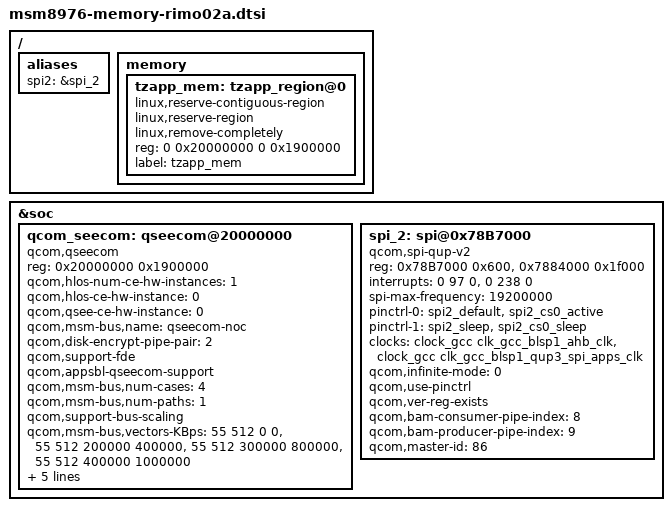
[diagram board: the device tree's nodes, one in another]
/ {
	aliases {
		spi2 = &spi_2; 
        };

	memory {
		tzapp_mem: tzapp_region@0 {
			linux,reserve-contiguous-region;
			linux,reserve-region;
			linux,remove-completely;
			reg = <0 0x20000000 0 0x1900000>;
			label = "tzapp_mem";
		};
        };
};

&soc {
        /delete-node/ qseecom@85b00000;

	qcom_seecom: qseecom@20000000 {
		compatible = "qcom,qseecom";
		reg = <0x20000000 0x1900000>;
		reg-names = "secapp-region";
		qcom,hlos-num-ce-hw-instances = <1>;
		qcom,hlos-ce-hw-instance = <0>;
		qcom,qsee-ce-hw-instance = <0>;
		qcom,msm-bus,name = "qseecom-noc";
		qcom,disk-encrypt-pipe-pair = <2>;
		qcom,support-fde;
		qcom,appsbl-qseecom-support;
		qcom,msm-bus,num-cases = <4>;
		qcom,msm-bus,num-paths = <1>;
		qcom,support-bus-scaling;
		qcom,msm-bus,vectors-KBps =
			<55 512 0 0>,
			<55 512 200000 400000>,
			<55 512 300000 800000>,
			<55 512 400000 1000000>;
		clocks = <&clock_gcc clk_crypto_clk_src>,
			 <&clock_gcc clk_gcc_crypto_clk>,
			 <&clock_gcc clk_gcc_crypto_ahb_clk>,
			 <&clock_gcc clk_gcc_crypto_axi_clk>;
		clock-names = "core_clk_src", "core_clk",
				"iface_clk", "bus_clk";
		qcom,ce-opp-freq = <100000000>;
        };

	spi_2: spi@0x78B7000 { /* BLSP1 QUP2 */
		compatible = "qcom,spi-qup-v2";
		reg-names = "spi_physical", "spi_bam_physical";
		reg = <0x78B7000 0x600>,
		      <0x7884000 0x1f000>;
		interrupt-names = "spi_irq", "spi_bam_irq";
		interrupts = <0 97 0>, <0 238 0>;
		spi-max-frequency = <19200000>;
		pinctrl-names = "spi_default", "spi_sleep";
		pinctrl-0 = <&spi2_default &spi2_cs0_active>;
		pinctrl-1 = <&spi2_sleep &spi2_cs0_sleep>;
		clocks = <&clock_gcc clk_gcc_blsp1_ahb_clk>,
			 <&clock_gcc clk_gcc_blsp1_qup3_spi_apps_clk>;
		clock-names = "iface_clk", "core_clk";
		qcom,infinite-mode = <0>;
		/*qcom,use-bam;*/
		qcom,use-pinctrl;
		qcom,ver-reg-exists;
		qcom,bam-consumer-pipe-index = <8>;
		qcom,bam-producer-pipe-index = <9>;
		qcom,master-id = <86>;
		status = "ok";
	};

};
